# D1H register map
Vendor: Allwinner; File version: 1.0
Registers are 32-bit, read-write, reset 0x0 unless marked. A register's access mark holds for its fields unless they carry their own. Offsets are from the block's base; [hi:lo] are bit positions; {n}, {i} and the like mark numbered series.

## RISCV_CFG — RISC-V System Configuration
Base 0x06010000
0x04 RISCV_STA_ADD0_REG — RISCV Start Address0 Register
0x08 RISCV_STA_ADD1_REG — RISCV Start Address1 Register
  [7:0] STA_ADD_H — Start Address High 8-bit
0x10 RF1P_CFG_REG — RF1P Configuration Register
  [7:0] RF1P_CFG — RF1P Configuration
0x1C ROM_CFG_REG — ROM Configuration Register
  [7:0] ROM_CFG — ROM Configuration
0x20 WAKEUP_EN_REG — Wakeup Enable Register
  [0] WP_EN — Wakeup Enable
{0x24+4i} WAKEUP_MASK{i}_REG (i=0..4) — Wakeup Mask Register
0x40 TS_TMODE_SEL_REG — Timestamp Test Mode Select Register
  [0] TS_TEST_MODE_EN — Timestamp Test Mode Enable
    0=Normal; 1=Test
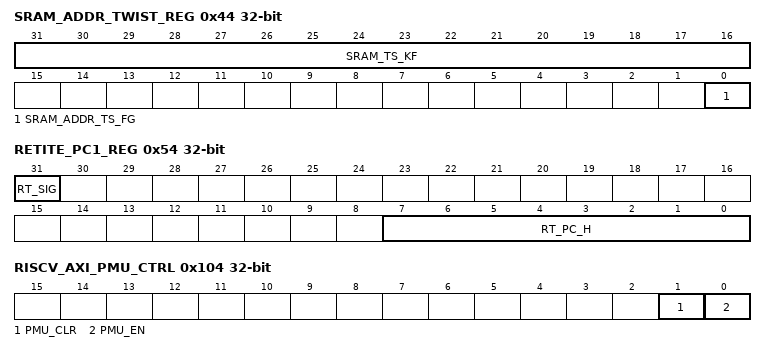
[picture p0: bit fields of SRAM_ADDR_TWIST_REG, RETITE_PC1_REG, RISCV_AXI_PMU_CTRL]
0x44 SRAM_ADDR_TWIST_REG — SRAM Address Twist Register
  [31:16] SRAM_TS_KF wo — SRAM Twist Keyfield
  [0] SRAM_ADDR_TS_FG — SRAM Address Twist Flag
0x48 WORK_MODE_REG ro — Work Mode Register
  [1:0] WM_STA — Work Mode Status
    0=Normal; 1=Low_Power; 2=Debug
0x50 RETITE_PC0_REG ro — Retire PC0 Register
0x54 RETITE_PC1_REG ro — Retire PC1 Register
  [31] RT_SIG — Retire Signal
    0=not_have; 1=have
  [7:0] RT_PC_H — Retire PC[39:32]
{0x60+4i} IRQ_MODE{i}_REG (i=0..4) — IRQ Mode Register
0x104 RISCV_AXI_PMU_CTRL — RISCV AXI PMU Control Register
  [1] PMU_CLR write-clears — PMU Clear
    0=no_operation; 1=cleared
  [0] PMU_EN — PMU Enable
    0=disabled; 1=enabled
0x108 RISCV_AXI_PMU_PRD — RISCV AXI PMU Period Register
0x10C RISCV_AXI_PMU_LAT_RD ro — RISCV AXI PMU Read Latency Register
0x110 RISCV_AXI_PMU_LAT_WR ro — RISCV AXI PMU Write Latency Register
0x114 RISCV_AXI_PMU_REQ_RD ro — RISCV AXI PMU Read Request Register
0x118 RISCV_AXI_PMU_REQ_WR ro — RISCV AXI PMU Write Request Register
0x11C RISCV_AXI_PMU_BW_RD ro — RISCV AXI PMU Read Bandwidth Register
0x120 RISCV_AXI_PMU_BW_WR ro — RISCV AXI PMU Write Bandwidth Register

## CLINT — Core-Local Interruptor
Base 0x14000000
0x00 msip range 0..1 — MSIP Register for hart 0
0x4000 mtimecmpl — MTIMECMPL Register for hart 0
0x4004 mtimecmph — MTIMECMPH Register for hart 0
0xBFF8 mtime 64-bit ro (reset mask 0xFFFFFFFF) — MTIME . REF: opensbi
0xC000 ssip range 0..1 — SSIP Register for hart 0
0xD000 stimecmpl — STIMECMPL Register for hart 0
0xD004 stimecmph — STIMECMPH Register for hart 0

## TIMER — Timer Module, includes timer0, timer1, watchdog and audio video synchronization
Base 0x02050000
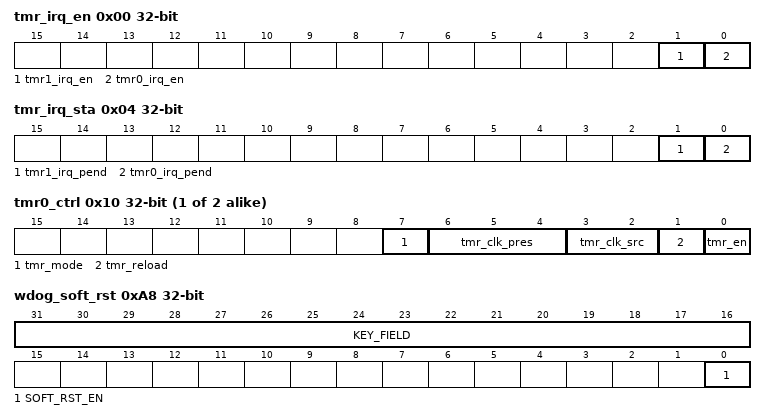
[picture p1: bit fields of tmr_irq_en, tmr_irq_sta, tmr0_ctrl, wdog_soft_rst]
0x00 tmr_irq_en — Timer IRQ Enable Register
  [1] tmr1_irq_en
    0=disabled; 1=enabled
  [0] tmr0_irq_en
    0=disabled; 1=enabled
0x04 tmr_irq_sta — Timer Status Register
  [1] tmr1_irq_pend
    0=no_effect; 1=pending (Indicates that the interval value of the timer 1 is reached. Write 1 to clear the pending status.)
  [0] tmr0_irq_pend
    0=no_effect; 1=pending (Indicates that the interval value of the timer 0 is reached. Write 1 to clear the pending status.)
{0x10+0x10*i} tmr{i}_ctrl (i=0..1) — Timer IRQ Enable Register
  [7] tmr_mode
    0=periodic; 1=single_counting
  [6:4] tmr_clk_pres
    0=P1; 1=P2; 2=P4; 3=P8; 4=P16; 5=P32; 6=P64; 7=P128
  [3:2] tmr_clk_src
    0=losc; 1=osc24_m
  [1] tmr_reload
    0=no_effect; 1=reload
  [0] tmr_en
    0=stop_pause; 1=start
{0x14+0x10*i} tmr{i}_intv_value (i=0..1) — Timer Interval Value Register
{0x18+0x10*i} tmr{i}_cur_value (i=0..1) — Timer Current Value Register
0xA0 wdog_irq_en — Watchdog IRQ Enable Register
  [0] wdog_irq_en
    0=disabled; 1=enabled
0xA4 wdog_irq_sta — Watchdog Status Register
  [0] wdog_irq_pend
    0=no_effect; 1=pending (Indicates that the interval value of the watchdog is reached.)
0xA8 wdog_soft_rst — Watchdog Software Reset Register
  [31:16] KEY_FIELD wo
  [0] SOFT_RST_EN — Soft Reset Enable
    0=Deassert; 1=Reset
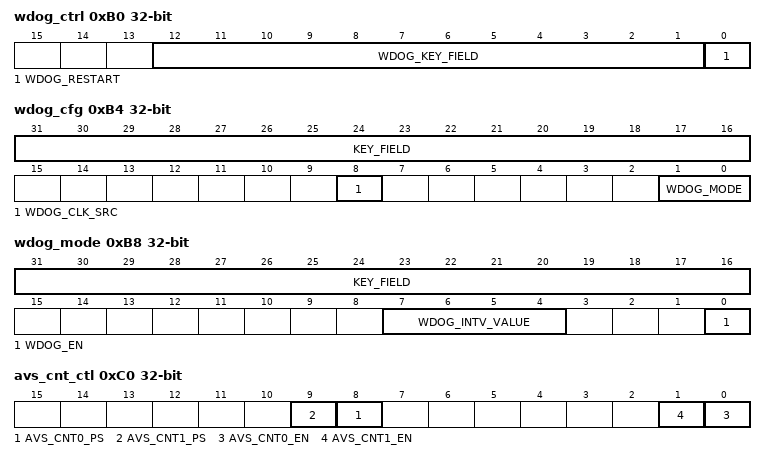
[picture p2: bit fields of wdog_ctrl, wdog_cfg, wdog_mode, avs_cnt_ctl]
0xB0 wdog_ctrl — Watchdog Control Register
  [12:1] WDOG_KEY_FIELD wo — Watchdog Key Field
  [0] WDOG_RESTART write-1-sets — Watchdog Restart
    0=no_effect; 1=restart
0xB4 wdog_cfg — Watchdog Configuration Register
  [31:16] KEY_FIELD wo
  [8] WDOG_CLK_SRC — Select the clock source for the watchdog.
    0=HOSC_32K; 1=LOSC_32K
  [1:0] WDOG_MODE — Configure the operating mode for the watchdog
    1=whold_system; 2=only_interrupt
0xB8 wdog_mode — Watchdog Mode Register
  [31:16] KEY_FIELD wo
  [7:4] WDOG_INTV_VALUE — Watchdog Interval Value
    0=C16000; 1=C32000; 2=C64000; 3=C96000; 4=C128000; 5=C160000; 6=C192000; 7=C256000; 8=C320000; 9=C384000; 10=C448000; 11=C512000
  [0] WDOG_EN — Watchdog Enable
    0=no_effect; 1=enable
0xBC wdog_output_cfg — Watchdog Output Configuration Register
  [11:0] WDOG_OUTPUT_CONFIG — Configure the valid time for the watchdog reset signal.
0xC0 avs_cnt_ctl — AVS Counter Control Register
  [n+8] AVS_CNT{n}_PS (n=0..1) — Audio Video Sync Counter Pause Control
    0=not_pause; 1=pause
  [n] AVS_CNT{n}_EN (n=0..1) — Audio Video Sync Counter Enable
    0=disabled; 1=enabled
0xC4 avs_cnt0 — AVS Counter 0 Register
0xC8 avs_cnt1 — AVS Counter 1 Register
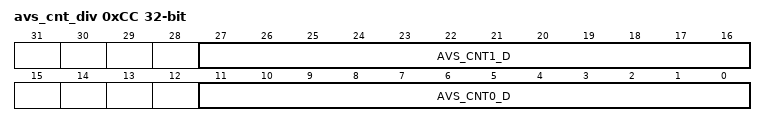
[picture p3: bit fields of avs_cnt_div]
0xCC avs_cnt_div — AVS Counter Divisor Register
  [16n+11:16n] AVS_CNT{n}_D (n=0..1) — The divisor factor of AVS
